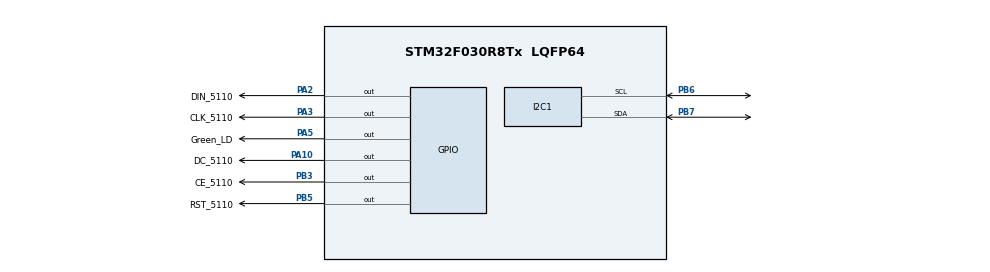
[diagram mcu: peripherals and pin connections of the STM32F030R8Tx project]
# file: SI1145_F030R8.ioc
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Mcu.Family=STM32F0
Mcu.Name=STM32F030R8Tx
Mcu.Package=LQFP64
PA10.GPIO_Label=DC_5110
PA10.Signal=GPIO_Output
PA2.GPIO_Label=DIN_5110
PA2.Signal=GPIO_Output
PA3.GPIO_Label=CLK_5110
PA3.Signal=GPIO_Output
PA5.GPIO_Label=Green_LD
PA5.Signal=GPIO_Output
PB3.GPIO_Label=CE_5110
PB3.Signal=GPIO_Output
PB5.GPIO_Label=RST_5110
PB5.Signal=GPIO_Output
PB6.Mode=I2C
PB6.Signal=I2C1_SCL
PB7.Mode=I2C
PB7.Signal=I2C1_SDA
ProjectManager.HeapSize=0x200
ProjectManager.StackSize=0x400
ProjectManager.TargetToolchain=STM32CubeIDE
board=NUCLEO-F030R8

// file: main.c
/* USER CODE BEGIN Header */
/**
  ******************************************************************************
  * @file           : main.c
  * @brief          : Main program body
  ******************************************************************************
  * @attention
  *
  * <h2><center>&copy; Copyright (c) 2020 STMicroelectronics.
  * All rights reserved.</center></h2>
  *
  * This software component is licensed by ST under BSD 3-Clause license,
  * the "License"; You may not use this file except in compliance with the
  * License. You may obtain a copy of the License at:
  *                        opensource.org/licenses/BSD-3-Clause
  *
  ******************************************************************************
  */
/* USER CODE END Header */

#include "main.h"

/* USER CODE BEGIN PM */
#include <SI1125_hal_lib.h>

uint16_t ir_value;
float uv_value;
uint16_t vis_value;

/* USER CODE END PM */

I2C_HandleTypeDef hi2c1;

void SystemClock_Config(void);
static void MX_GPIO_Init(void);
static void MX_I2C1_Init(void);

int main(void)
{

  /* MCU Configuration--------------------------------------------------------*/

  /* Reset of all peripherals, Initializes the Flash interface and the Systick. */
  HAL_Init();

  /* Configure the system clock */
  SystemClock_Config();

  /* Initialize all configured peripherals */
  MX_GPIO_Init();
  MX_I2C1_Init();
  /* USER CODE BEGIN 2 */
  SI1125_begin();
  /* USER CODE END 2 */

  /* Infinite loop */
  while (1)
  {

    /* USER CODE BEGIN 3 */
	  uint8_t temp[10];
	  ir_value = SI1125_readIR();
	  uv_value = SI1125_readUV()/100.0;
	  vis_value = SI1125_readVisible();

	  HAL_Delay(200);

	  HAL_GPIO_TogglePin(Green_LD_GPIO_Port, Green_LD_Pin);
  }
  /* USER CODE END 3 */
}

void SystemClock_Config(void)
{
  RCC_OscInitTypeDef RCC_OscInitStruct = {0};
  RCC_ClkInitTypeDef RCC_ClkInitStruct = {0};
  RCC_PeriphCLKInitTypeDef PeriphClkInit = {0};

  /** Initializes the CPU, AHB and APB busses clocks
  */
  RCC_OscInitStruct.OscillatorType = RCC_OSCILLATORTYPE_HSI;
  RCC_OscInitStruct.HSIState = RCC_HSI_ON;
  RCC_OscInitStruct.HSICalibrationValue = RCC_HSICALIBRATION_DEFAULT;
  RCC_OscInitStruct.PLL.PLLState = RCC_PLL_NONE;
  if (HAL_RCC_OscConfig(&RCC_OscInitStruct) != HAL_OK)
  {
    Error_Handler();
  }
  /** Initializes the CPU, AHB and APB busses clocks
  */
  RCC_ClkInitStruct.ClockType = RCC_CLOCKTYPE_HCLK|RCC_CLOCKTYPE_SYSCLK
                              |RCC_CLOCKTYPE_PCLK1;
  RCC_ClkInitStruct.SYSCLKSource = RCC_SYSCLKSOURCE_HSI;
  RCC_ClkInitStruct.AHBCLKDivider = RCC_SYSCLK_DIV1;
  RCC_ClkInitStruct.APB1CLKDivider = RCC_HCLK_DIV1;

  if (HAL_RCC_ClockConfig(&RCC_ClkInitStruct, FLASH_LATENCY_0) != HAL_OK)
  {
    Error_Handler();
  }
  PeriphClkInit.PeriphClockSelection = RCC_PERIPHCLK_I2C1;
  PeriphClkInit.I2c1ClockSelection = RCC_I2C1CLKSOURCE_HSI;
  if (HAL_RCCEx_PeriphCLKConfig(&PeriphClkInit) != HAL_OK)
  {
    Error_Handler();
  }
}

static void MX_I2C1_Init(void)
{

  hi2c1.Instance = I2C1;
  hi2c1.Init.Timing = 0x2000090E;
  hi2c1.Init.OwnAddress1 = 0;
  hi2c1.Init.AddressingMode = I2C_ADDRESSINGMODE_7BIT;
  hi2c1.Init.DualAddressMode = I2C_DUALADDRESS_DISABLE;
  hi2c1.Init.OwnAddress2 = 0;
  hi2c1.Init.OwnAddress2Masks = I2C_OA2_NOMASK;
  hi2c1.Init.GeneralCallMode = I2C_GENERALCALL_DISABLE;
  hi2c1.Init.NoStretchMode = I2C_NOSTRETCH_DISABLE;
  if (HAL_I2C_Init(&hi2c1) != HAL_OK)
  {
    Error_Handler();
  }
  /** Configure Analogue filter
  */
  if (HAL_I2CEx_ConfigAnalogFilter(&hi2c1, I2C_ANALOGFILTER_ENABLE) != HAL_OK)
  {
    Error_Handler();
  }
  /** Configure Digital filter
  */
  if (HAL_I2CEx_ConfigDigitalFilter(&hi2c1, 0) != HAL_OK)
  {
    Error_Handler();
  }

}

static void MX_GPIO_Init(void)
{
  GPIO_InitTypeDef GPIO_InitStruct = {0};

  /* GPIO Ports Clock Enable */
  __HAL_RCC_GPIOA_CLK_ENABLE();
  __HAL_RCC_GPIOB_CLK_ENABLE();

  /*Configure GPIO pin Output Level */
  HAL_GPIO_WritePin(GPIOA, DIN_5110_Pin|CLK_5110_Pin|Green_LD_Pin|DC_5110_Pin, GPIO_PIN_RESET);

  /*Configure GPIO pin Output Level */
  HAL_GPIO_WritePin(GPIOB, CE_5110_Pin|RST_5110_Pin, GPIO_PIN_RESET);

  /*Configure GPIO pins : DIN_5110_Pin CLK_5110_Pin Green_LD_Pin DC_5110_Pin */
  GPIO_InitStruct.Pin = DIN_5110_Pin|CLK_5110_Pin|Green_LD_Pin|DC_5110_Pin;
  GPIO_InitStruct.Mode = GPIO_MODE_OUTPUT_PP;
  GPIO_InitStruct.Pull = GPIO_NOPULL;
  GPIO_InitStruct.Speed = GPIO_SPEED_FREQ_LOW;
  HAL_GPIO_Init(GPIOA, &GPIO_InitStruct);

  /*Configure GPIO pins : CE_5110_Pin RST_5110_Pin */
  GPIO_InitStruct.Pin = CE_5110_Pin|RST_5110_Pin;
  GPIO_InitStruct.Mode = GPIO_MODE_OUTPUT_PP;
  GPIO_InitStruct.Pull = GPIO_NOPULL;
  GPIO_InitStruct.Speed = GPIO_SPEED_FREQ_LOW;
  HAL_GPIO_Init(GPIOB, &GPIO_InitStruct);

}

void Error_Handler(void)
{
}

/************************ (C) COPYRIGHT STMicroelectronics *****END OF FILE****/
